# S32K312_M7 register map
Vendor: NXP Semiconductors; File version: 1.4
CPU: CM7 r0p1, little endian, MPU, FPU, VTOR, 4 interrupt priority bits
Registers are 32-bit, read-write, reset 0x0 unless marked. A register's access mark holds for its fields unless they carry their own. Offsets are from the block's base; [hi:lo] are bit positions; {n}, {i} and the like mark numbered series; 'fields as' and 'values as' point back to an identical list.

## PLL — PLLDIG
Base 0x402E0000
0x00 PLLCR reset 0x80000000 — PLL Control
  [31] PLLPD — PLL Power Down
    0=bfv_pllcr_pllpd_0 (Powered up); 1=bfv_pllcr_pllpd_1 (Powered down)
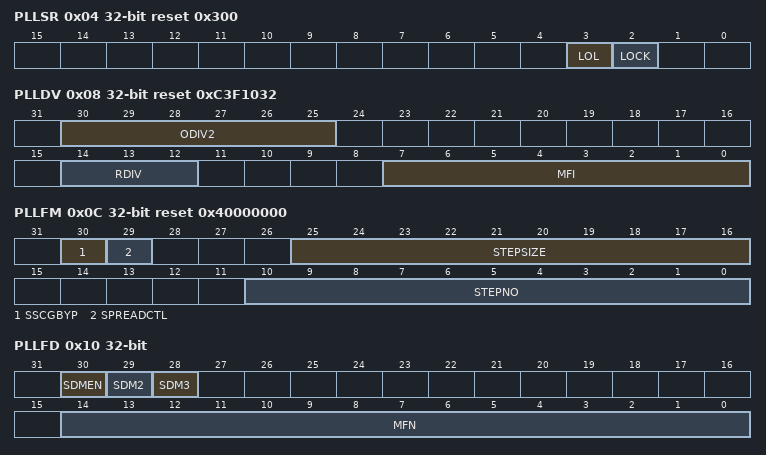
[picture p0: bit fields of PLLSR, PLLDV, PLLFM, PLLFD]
0x04 PLLSR reset 0x300 — PLL Status
  [3] LOL write-1-clears — Loss-Of-Lock Flag
    0=bfv_pllsr_lol_0 (No loss of lock detected); 1=bfv_pllsr_lol_1 (Loss of lock detected)
  [2] LOCK ro — Lock Status
    0=bfv_pllsr_lock_0 (Unlocked); 1=bfv_pllsr_lock_1 (Locked)
0x08 PLLDV reset 0xC3F1032 — PLL Divider
  [30:25] ODIV2 — Output frequency divider for raw PLL clock.
  [14:12] RDIV — Input Clock Predivider
    0=bfv_plldv_rdiv_000 (Divide by 1); 1=bfv_plldv_rdiv_001 (Divide by 1); 2=bfv_plldv_rdiv_010 (Divide by 2); 3=bfv_plldv_rdiv_011 (Divide by 3); 4=bfv_plldv_rdiv_100 (Divide by 4); 5=bfv_plldv_rdiv_101 (Divide by 5); 6=bfv_plldv_rdiv_110 (Divide by 6); 7=bfv_plldv_rdiv_111 (Divide by 7)
  [7:0] MFI — Integer Portion Of Loop Divider
0x0C PLLFM reset 0x40000000 — PLL Frequency Modulation
  [30] SSCGBYP — Frequency Modulation (Spread Spectrum Clock Generation) Bypass
    0=bfv_pllfm_sscgbyp_0 (Not bypassed); 1=bfv_pllfm_sscgbyp_1 (Bypassed)
  [29] SPREADCTL — Modulation Type Selection
    1=bfv_pllfm_spreadctl_1 (Spread below nominal frequency)
  [25:16] STEPSIZE — Frequency Modulation Step Size
  [10:0] STEPNO — Number Of Steps Of Modulation Period Or Frequency Modulation
0x10 PLLFD — PLL Fractional Divider
  [30] SDMEN — Fractional Mode Enable
    0=bfv_pllfd_sdmen_0 (Disabled); 1=bfv_pllfd_sdmen_1 (Enabled)
  [29] SDM2 — Fractional Mode Configuration
  [28] SDM3 — Fractional Mode Configuration
  [14:0] MFN — Numerator Of Fractional Loop Division Factor
0x18 PLLCAL2 reset 0x60000 — PLL Calibration Register 2
  [8:7] ULKCTL — Unlock Control Accuracy
    0=bfv_pllcal2_ulkctl_00 (Unlock range = Expected value +/- 9 (recommended when PLLFM[SSCGBYP] = 1)); 1=bfv_pllcal2_ulkctl_01 (Unlock range = Expected value +/- 17 (recommended when PLLFM[SSCGBYP] = 0)); 2=bfv_pllcal2_ulkctl_10 (Unlock range = Expected value +/- 33); 3=bfv_pllcal2_ulkctl_11 (Unlock range = Expected value +/- 5)
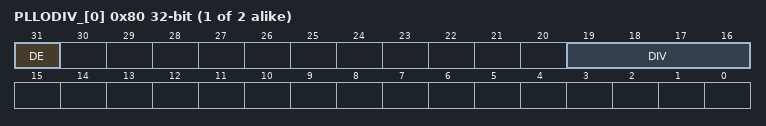
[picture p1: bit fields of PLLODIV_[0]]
{0x80+4i} PLLODIV_[{i}] (i=0..1) — PLL Output Divider
  [31] DE — Divider Enable
    0=bfv_pllodiv_de_0 (Disabled); 1=bfv_pllodiv_de_1 (Enabled)
  [19:16] DIV — Division Value

## PMC
Base 0x402E8000
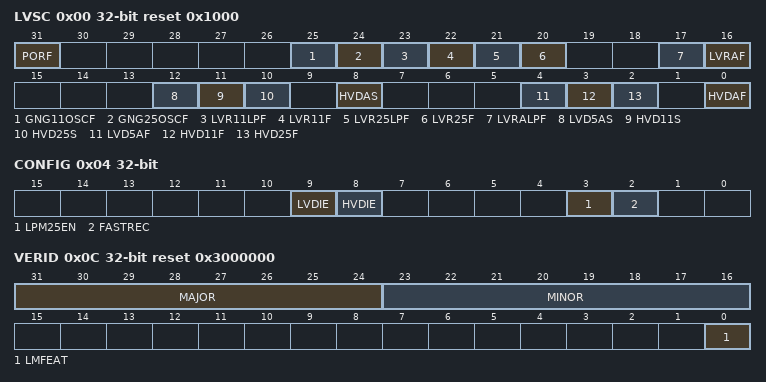
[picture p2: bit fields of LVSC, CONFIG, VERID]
0x00 LVSC reset 0x1000 (reset mask 0x7C0CFFFF) — Low Voltage Status And Control
  [31] PORF write-1-clears — POR Flag
    on read: 0=EVENT_NO (Event did not occur); 1=EVENT_YES (Event occurred)
  [25] GNG11OSCF write-1-clears — Go/No Go Detect Flag On OSC Part Of V11 Power Domain
    values as PORF
  [24] GNG25OSCF write-1-clears — Go/No Go Detect Flag On OSC Part of V25 Power Domain
    values as PORF
  [23] LVR11LPF write-1-clears — LVR11LP Flag On V11 Power Domain
    values as PORF
  [22] LVR11F write-1-clears — LVR11 Flag On V11 Power Domain In FPM
    values as PORF
  [21] LVR25LPF write-1-clears — LVR25LP Flag On V25 Power Domain
    values as PORF
  [20] LVR25F write-1-clears — LVR25 Flag On V25 Power Domain In FPM
    values as PORF
  [17] LVRALPF write-1-clears — LVRALP Flag On VDD_HV_A Power Domain
    values as PORF
  [16] LVRAF write-1-clears — LVRA Flag On VDD_HV_A Power Domain In FPM
    values as PORF
  [12] LVD5AS ro — LVD5A Status On VDD_HV_A Power Domain In FPM
    0=VOLTAGE_HIGH_TYP5 (Above); 1=VOLTAGE_LOW_TYP33 (Below)
  [11] HVD11S ro — HVD11 Status On V11 Power Domain In FPM
    0=VOLTAGE_GOOD (Voltage is below threshold or chip is in LPM); 1=VOLTAGE_TOO_HIGH (Voltage is above threshold and chip is in FPM)
  [10] HVD25S ro — HVD25 Status On V25 Power Domain In FPM
    values as HVD11S
  [8] HVDAS ro — HVDA Status On VDD_HV_A Power Domain In FPM
    values as HVD11S
  [4] LVD5AF write-1-clears — LVD5A Flag On VDD_HV_A Power Domain In FPM
    on read: 0=CHANGE_NO (Did not change); 1=CHANGE_YES (Changed)
  [3] HVD11F write-1-clears — HVD11 Flag On V11 Power Domain In FPM
    values as LVD5AF
  [2] HVD25F write-1-clears — HVD25 Flag On V25 Power Domain In FPM
    values as LVD5AF
  [0] HVDAF write-1-clears — HVDA Flag On VDD_HV_A Power Domain In FPM
    values as LVD5AF
0x04 CONFIG — PMC Configuration
  [9] LVDIE — Low Voltage Detect Interrupt Enable
    0=DISABLE (LVD hardware interrupt is disabled (use polling)); 1=ENABLE (Request an LVD hardware interrupt when LVDA5F = 1)
  [8] HVDIE — High Voltage Detect Interrupt Enable
    0=DISABLE (HVD hardware interrupt is disabled (use polling)); 1=ENABLE (Request an HVD hardware interrupt when HVDAF=1, HVDBF=1, HVD25F=1, or HVD11F=1)
  [3] LPM25EN — V25 Power Domain Enable During LPM
    0=DISABLE (Disabled); 1=ENABLE (Enabled)
  [2] FASTREC — Fast Recovery From LPM Enable
    0=DISABLE (Normal); 1=ENABLE (Fast)
0x0C VERID ro reset 0x3000000 — Version ID
  [31:24] MAJOR — Major Version Number
  [23:16] MINOR — Minor Version Number
  [0] LMFEAT — Last-Mile Regulator Feature
    0=DISABLE (Not available); 1=ENABLE (Available)
